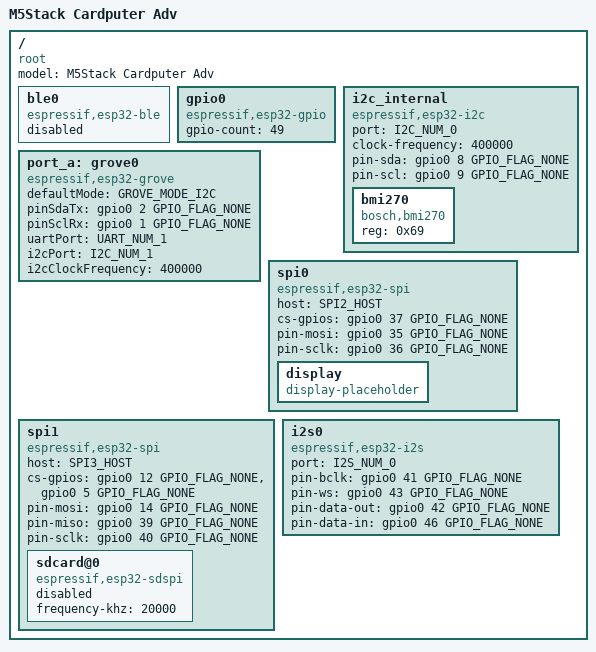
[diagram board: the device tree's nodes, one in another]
/dts-v1/;

#include <tactility/bindings/root.h>
#include <tactility/bindings/esp32_ble.h>
#include <tactility/bindings/esp32_gpio.h>
#include <tactility/bindings/esp32_grove.h>
#include <tactility/bindings/esp32_i2c.h>
#include <tactility/bindings/esp32_i2s.h>
#include <tactility/bindings/esp32_spi.h>
#include <tactility/bindings/esp32_uart.h>
#include <bindings/bmi270.h>
#include <tactility/bindings/esp32_sdspi.h>
#include <tactility/bindings/display_placeholder.h>

// Reference: https://docs.m5stack.com/en/core/Cardputer-Adv
/ {
	compatible = "root";
	model = "M5Stack Cardputer Adv";

	ble0 {
		compatible = "espressif,esp32-ble";
		status = "disabled";
	};

	gpio0 {
		compatible = "espressif,esp32-gpio";
		gpio-count = <49>;
	};

	i2c_internal {
		compatible = "espressif,esp32-i2c";
		port = <I2C_NUM_0>;
		clock-frequency = <400000>;
		pin-sda = <&gpio0 8 GPIO_FLAG_NONE>;
		pin-scl = <&gpio0 9 GPIO_FLAG_NONE>;

		bmi270 {
			compatible = "bosch,bmi270";
			reg = <0x69>;
		};
	};

	port_a: grove0 {
		compatible = "espressif,esp32-grove";
		defaultMode = <GROVE_MODE_I2C>;
		pinSdaTx = <&gpio0 2 GPIO_FLAG_NONE>;
		pinSclRx = <&gpio0 1 GPIO_FLAG_NONE>;
		uartPort = <UART_NUM_1>;
		i2cPort = <I2C_NUM_1>;
		i2cClockFrequency = <400000>;
	};

	spi0 {
		compatible = "espressif,esp32-spi";
		host = <SPI2_HOST>;
		cs-gpios = <&gpio0 37 GPIO_FLAG_NONE>;
		pin-mosi = <&gpio0 35 GPIO_FLAG_NONE>;
		pin-sclk = <&gpio0 36 GPIO_FLAG_NONE>;
	
		display {
			compatible = "display-placeholder";
		};
	};

	spi1 {
		compatible = "espressif,esp32-spi";
		host = <SPI3_HOST>;
		cs-gpios = <&gpio0 12 GPIO_FLAG_NONE>,
		           <&gpio0 5 GPIO_FLAG_NONE>;
		pin-mosi = <&gpio0 14 GPIO_FLAG_NONE>;
		pin-miso = <&gpio0 39 GPIO_FLAG_NONE>;
		pin-sclk = <&gpio0 40 GPIO_FLAG_NONE>;
	
		sdcard@0 {
			compatible = "espressif,esp32-sdspi";
			status = "disabled";
			frequency-khz = <20000>;
		};
	};

	// Speaker and microphone (ES8311)
	i2s0 {
		compatible = "espressif,esp32-i2s";
		port = <I2S_NUM_0>;
		pin-bclk = <&gpio0 41 GPIO_FLAG_NONE>;
		pin-ws = <&gpio0 43 GPIO_FLAG_NONE>;
		pin-data-out = <&gpio0 42 GPIO_FLAG_NONE>;
		pin-data-in = <&gpio0 46 GPIO_FLAG_NONE>;
	};
};
